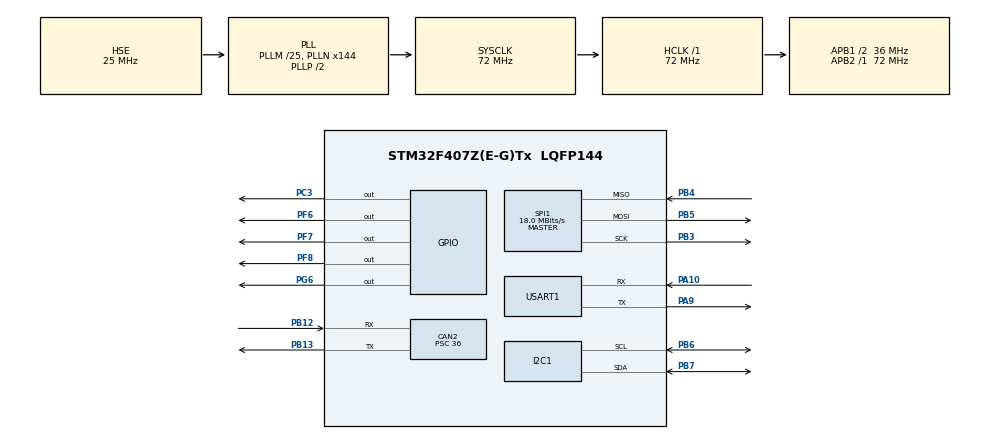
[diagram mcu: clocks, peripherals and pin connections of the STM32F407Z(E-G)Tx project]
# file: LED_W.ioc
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CAN2.ABOM=ENABLE
CAN2.AWUM=ENABLE
CAN2.BS1=CAN_BS1_2TQ
CAN2.BS2=CAN_BS2_2TQ
CAN2.CalculateBaudRate=200000
CAN2.CalculateTimeBit=5000
CAN2.CalculateTimeQuantum=1000.0
CAN2.Mode=CAN_MODE_NORMAL
CAN2.Prescaler=36
Mcu.Family=STM32F4
Mcu.Name=STM32F407Z(E-G)Tx
Mcu.Package=LQFP144
NVIC.PriorityGroup=NVIC_PRIORITYGROUP_4
NVIC.USART1_IRQn=true\:5\:0\:true\:false\:true\:true\:true\:true
PA10.Mode=Asynchronous
PA10.Signal=USART1_RX
PA13.Mode=Serial_Wire
PA13.Signal=SYS_JTMS-SWDIO
PA14.Mode=Serial_Wire
PA14.Signal=SYS_JTCK-SWCLK
PA9.Mode=Asynchronous
PA9.Signal=USART1_TX
PB12.Mode=CAN_Activate
PB12.Signal=CAN2_RX
PB13.Mode=CAN_Activate
PB13.Signal=CAN2_TX
PB3.Mode=Full_Duplex_Master
PB3.Signal=SPI1_SCK
PB4.Mode=Full_Duplex_Master
PB4.Signal=SPI1_MISO
PB5.Mode=Full_Duplex_Master
PB5.Signal=SPI1_MOSI
PB6.Mode=I2C
PB6.Signal=I2C1_SCL
PB7.Mode=I2C
PB7.Signal=I2C1_SDA
PC14-OSC32_IN.Mode=LSE-External-Oscillator
PC14-OSC32_IN.Signal=RCC_OSC32_IN
PC15-OSC32_OUT.Mode=LSE-External-Oscillator
PC15-OSC32_OUT.Signal=RCC_OSC32_OUT
PC3.PinState=GPIO_PIN_SET
PC3.Signal=GPIO_Output
PF6.PinState=GPIO_PIN_SET
PF6.Signal=GPIO_Output
PF7.PinState=GPIO_PIN_SET
PF7.Signal=GPIO_Output
PF8.PinState=GPIO_PIN_SET
PF8.Signal=GPIO_Output
PG6.GPIO_Speed=GPIO_SPEED_FREQ_HIGH
PG6.PinState=GPIO_PIN_SET
PG6.Signal=GPIO_Output
PH0-OSC_IN.Mode=HSE-External-Oscillator
PH0-OSC_IN.Signal=RCC_OSC_IN
PH1-OSC_OUT.Mode=HSE-External-Oscillator
PH1-OSC_OUT.Signal=RCC_OSC_OUT
ProjectManager.HeapSize=0x200
ProjectManager.StackSize=0x400
ProjectManager.TargetToolchain=MDK-ARM V5.32
RCC.48MHZClocksFreq_Value=36000000
RCC.AHBFreq_Value=72000000
RCC.APB1CLKDivider=RCC_HCLK_DIV2
RCC.APB1Freq_Value=36000000
RCC.APB1TimFreq_Value=72000000
RCC.APB2Freq_Value=72000000
RCC.APB2TimFreq_Value=72000000
RCC.CortexFreq_Value=72000000
RCC.HCLKFreq_Value=72000000
RCC.HSE_VALUE=25000000
RCC.HSI_VALUE=16000000
RCC.PLLM=25
RCC.PLLN=144
RCC.PLLSourceVirtual=RCC_PLLSOURCE_HSE
RCC.SYSCLKFreq_VALUE=72000000
RCC.SYSCLKSource=RCC_SYSCLKSOURCE_PLLCLK
RCC.VCOOutputFreq_Value=144000000
SPI1.BaudRatePrescaler=SPI_BAUDRATEPRESCALER_4
SPI1.CalculateBaudRate=18.0 MBits/s
SPI1.Direction=SPI_DIRECTION_2LINES
SPI1.Mode=SPI_MODE_MASTER
SPI1.VirtualType=VM_MASTER
USART1.VirtualMode=VM_ASYNC
VP_CRC_VS_CRC.Mode=CRC_Activate
board=custom

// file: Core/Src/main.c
/* USER CODE BEGIN Header */
/**
  ******************************************************************************
  * @file           : main.c
  * @brief          : Main program body
  ******************************************************************************
  * @attention
  *
  * Copyright (c) 2026 STMicroelectronics.
  * All rights reserved.
  *
  * This software is licensed under terms that can be found in the LICENSE file
  * in the root directory of this software component.
  * If no LICENSE file comes with this software, it is provided AS-IS.
  *
  ******************************************************************************
  */
/* USER CODE END Header */
#include "main.h"
#include "can.h"
#include "crc.h"
#include "i2c.h"
#include "spi.h"
#include "usart.h"
#include "gpio.h"

/* USER CODE BEGIN Includes */
#include <stdio.h>
#include "Int_can2.h"
#include "app_update.h"

/* USER CODE END Includes */

void SystemClock_Config(void);

int main(void)
{

  /* USER CODE BEGIN 1 */

__enable_irq();
  /* USER CODE END 1 */

  /* MCU Configuration--------------------------------------------------------*/

  /* Reset of all peripherals, Initializes the Flash interface and the Systick. */
  HAL_Init();

  /* Configure the system clock */
  SystemClock_Config();

  /* Initialize all configured peripherals */
  MX_GPIO_Init();
  MX_CAN2_Init();
  MX_USART1_UART_Init();
  MX_CRC_Init();
  MX_I2C1_Init();
  MX_SPI1_Init();
  /* USER CODE BEGIN 2 */
  App_Update(); //调用App_Update函数，启动串口接收程序，等待接收更新指令
  /* USER CODE END 2 */

  /* Infinite loop */
  /* USER CODE BEGIN WHILE */
  while (1)
  {
    App_Update_Work(); //循环调用执行状态机
    /* USER CODE END WHILE */

  }
}

void SystemClock_Config(void)
{
  RCC_OscInitTypeDef RCC_OscInitStruct = {0};
  RCC_ClkInitTypeDef RCC_ClkInitStruct = {0};

  /** Configure the main internal regulator output voltage
  */
  __HAL_RCC_PWR_CLK_ENABLE();
  __HAL_PWR_VOLTAGESCALING_CONFIG(PWR_REGULATOR_VOLTAGE_SCALE1);

  /** Initializes the RCC Oscillators according to the specified parameters
  * in the RCC_OscInitTypeDef structure.
  */
  RCC_OscInitStruct.OscillatorType = RCC_OSCILLATORTYPE_HSE;
  RCC_OscInitStruct.HSEState = RCC_HSE_ON;
  RCC_OscInitStruct.PLL.PLLState = RCC_PLL_ON;
  RCC_OscInitStruct.PLL.PLLSource = RCC_PLLSOURCE_HSE;
  RCC_OscInitStruct.PLL.PLLM = 25;
  RCC_OscInitStruct.PLL.PLLN = 144;
  RCC_OscInitStruct.PLL.PLLP = RCC_PLLP_DIV2;
  RCC_OscInitStruct.PLL.PLLQ = 4;
  if (HAL_RCC_OscConfig(&RCC_OscInitStruct) != HAL_OK)
  {
    Error_Handler();
  }

  /** Initializes the CPU, AHB and APB buses clocks
  */
  RCC_ClkInitStruct.ClockType = RCC_CLOCKTYPE_HCLK|RCC_CLOCKTYPE_SYSCLK
                              |RCC_CLOCKTYPE_PCLK1|RCC_CLOCKTYPE_PCLK2;
  RCC_ClkInitStruct.SYSCLKSource = RCC_SYSCLKSOURCE_PLLCLK;
  RCC_ClkInitStruct.AHBCLKDivider = RCC_SYSCLK_DIV1;
  RCC_ClkInitStruct.APB1CLKDivider = RCC_HCLK_DIV2;
  RCC_ClkInitStruct.APB2CLKDivider = RCC_HCLK_DIV1;

  if (HAL_RCC_ClockConfig(&RCC_ClkInitStruct, FLASH_LATENCY_2) != HAL_OK)
  {
    Error_Handler();
  }
}

void Error_Handler(void)
{
  __disable_irq();
  while (1)
  {
  }
}
